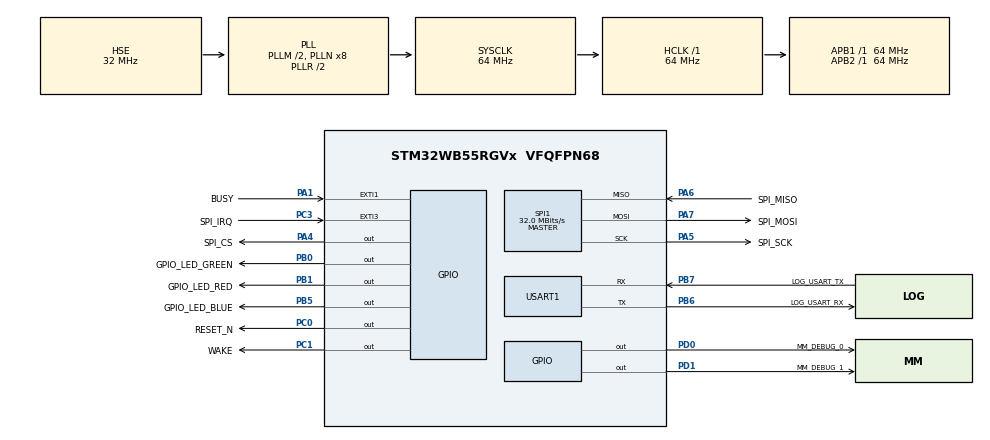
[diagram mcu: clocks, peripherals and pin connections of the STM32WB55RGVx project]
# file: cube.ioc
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Dma.Request0=SPI1_RX
Dma.Request1=SPI1_TX
Dma.SPI1_RX.0.Direction=DMA_PERIPH_TO_MEMORY
Dma.SPI1_RX.0.EventEnable=DISABLE
Dma.SPI1_RX.0.Instance=DMA1_Channel1
Dma.SPI1_RX.0.MemDataAlignment=DMA_MDATAALIGN_BYTE
Dma.SPI1_RX.0.MemInc=DMA_MINC_ENABLE
Dma.SPI1_RX.0.Mode=DMA_NORMAL
Dma.SPI1_RX.0.PeriphDataAlignment=DMA_PDATAALIGN_BYTE
Dma.SPI1_RX.0.PeriphInc=DMA_PINC_DISABLE
Dma.SPI1_RX.0.Polarity=HAL_DMAMUX_REQ_GEN_RISING
Dma.SPI1_RX.0.Priority=DMA_PRIORITY_LOW
Dma.SPI1_RX.0.RequestNumber=1
Dma.SPI1_RX.0.SignalID=NONE
Dma.SPI1_RX.0.SyncEnable=DISABLE
Dma.SPI1_RX.0.SyncPolarity=HAL_DMAMUX_SYNC_NO_EVENT
Dma.SPI1_RX.0.SyncRequestNumber=1
Dma.SPI1_RX.0.SyncSignalID=NONE
Dma.SPI1_TX.1.Direction=DMA_MEMORY_TO_PERIPH
Dma.SPI1_TX.1.EventEnable=DISABLE
Dma.SPI1_TX.1.Instance=DMA1_Channel2
Dma.SPI1_TX.1.MemDataAlignment=DMA_MDATAALIGN_BYTE
Dma.SPI1_TX.1.MemInc=DMA_MINC_ENABLE
Dma.SPI1_TX.1.Mode=DMA_NORMAL
Dma.SPI1_TX.1.PeriphDataAlignment=DMA_PDATAALIGN_BYTE
Dma.SPI1_TX.1.PeriphInc=DMA_PINC_DISABLE
Dma.SPI1_TX.1.Polarity=HAL_DMAMUX_REQ_GEN_RISING
Dma.SPI1_TX.1.Priority=DMA_PRIORITY_LOW
Dma.SPI1_TX.1.RequestNumber=1
Dma.SPI1_TX.1.SignalID=NONE
Dma.SPI1_TX.1.SyncEnable=DISABLE
Dma.SPI1_TX.1.SyncPolarity=HAL_DMAMUX_SYNC_NO_EVENT
Dma.SPI1_TX.1.SyncRequestNumber=1
Dma.SPI1_TX.1.SyncSignalID=NONE
Mcu.Family=STM32WB
Mcu.Name=STM32WB55RGVx
Mcu.Package=VFQFPN68
NVIC.DMA1_Channel1_IRQn=true\:15\:0\:true\:false\:false\:false\:true\:true
NVIC.EXTI1_IRQn=true\:15\:0\:true\:false\:false\:true\:true\:false
NVIC.EXTI3_IRQn=true\:15\:0\:true\:false\:false\:true\:true\:false
NVIC.HSEM_IRQn=true\:5\:0\:true\:false\:true\:false\:true\:true
NVIC.IPCC_C1_RX_IRQn=true\:5\:0\:true\:false\:true\:true\:true\:true
NVIC.IPCC_C1_TX_IRQn=true\:5\:0\:true\:false\:true\:true\:true\:true
NVIC.PriorityGroup=NVIC_PRIORITYGROUP_4
NVIC.TIM1_UP_TIM16_IRQn=true\:15\:0\:false\:false\:true\:false\:true\:true
NVIC.TimeBase=TIM1_UP_TIM16_IRQn
NVIC.TimeBaseIP=TIM1
NVIC.USART1_IRQn=true\:15\:0\:true\:false\:false\:true\:true\:true
OSC_IN.Mode=HSE-External-Oscillator
OSC_IN.Signal=RCC_OSC_IN
OSC_OUT.Mode=HSE-External-Oscillator
OSC_OUT.Signal=RCC_OSC_OUT
PA1.GPIO_Label=BUSY
PA1.GPIO_PuPd=GPIO_PULLDOWN
PA1.Signal=GPXTI1
PA13.GPIO_Label=JTMS
PA13.Mode=Serial_Wire
PA13.Signal=SYS_JTMS-SWDIO
PA14.GPIO_Label=JTCK
PA14.Mode=Serial_Wire
PA14.Signal=SYS_JTCK-SWCLK
PA4.GPIO_Label=SPI_CS
PA4.Signal=GPIO_Output
PA5.GPIO_Label=SPI_SCK
PA5.GPIO_Speed=GPIO_SPEED_FREQ_VERY_HIGH
PA5.Mode=Full_Duplex_Master
PA5.Signal=SPI1_SCK
PA6.GPIO_Label=SPI_MISO
PA6.GPIO_Speed=GPIO_SPEED_FREQ_VERY_HIGH
PA6.Mode=Full_Duplex_Master
PA6.Signal=SPI1_MISO
PA7.GPIO_Label=SPI_MOSI
PA7.GPIO_Speed=GPIO_SPEED_FREQ_VERY_HIGH
PA7.Mode=Full_Duplex_Master
PA7.Signal=SPI1_MOSI
PB0.GPIO_Label=GPIO_LED_GREEN
PB0.Signal=GPIO_Output
PB1.GPIO_Label=GPIO_LED_RED
PB1.Signal=GPIO_Output
PB3.GPIO_Label=JTDO
PB3.Signal=SYS_JTDO-SWO
PB5.GPIO_Label=GPIO_LED_BLUE
PB5.Signal=GPIO_Output
PB6.GPIO_Label=LOG_USART_RX
PB6.GPIO_PuPd=GPIO_NOPULL
PB6.Mode=Asynchronous
PB6.Signal=USART1_TX
PB7.GPIO_Label=LOG_USART_TX
PB7.GPIO_PuPd=GPIO_NOPULL
PB7.Mode=Asynchronous
PB7.Signal=USART1_RX
PC0.GPIO_Label=RESET_N
PC0.Signal=GPIO_Output
PC1.GPIO_Label=WAKE
PC1.Signal=GPIO_Output
PC14-OSC32_IN.Mode=LSE-External-Oscillator
PC14-OSC32_IN.Signal=RCC_OSC32_IN
PC15-OSC32_OUT.Mode=LSE-External-Oscillator
PC15-OSC32_OUT.Signal=RCC_OSC32_OUT
PC3.GPIO_Label=SPI_IRQ
PC3.GPIO_ModeDefaultEXTI=GPIO_MODE_IT_FALLING
PC3.Signal=GPXTI3
PD0.GPIO_Label=MM_DEBUG_0
PD0.Signal=GPIO_Output
PD1.GPIO_Label=MM_DEBUG_1
PD1.Signal=GPIO_Output
ProjectManager.HeapSize=0x200
ProjectManager.StackSize=0x400
ProjectManager.TargetToolchain=STM32CubeIDE
RCC.ADCFreq_Value=192000000
RCC.AHB2CLKDivider=RCC_SYSCLK_DIV2
RCC.AHBFreq_Value=64000000
RCC.APB1Freq_Value=64000000
RCC.APB1TimFreq_Value=64000000
RCC.APB2Freq_Value=64000000
RCC.APB2TimFreq_Value=64000000
RCC.APB3Freq_Value=16000000
RCC.CK48CLockSelection=RCC_USBCLKSOURCE_HSI48
RCC.CortexFreq_Value=64000000
RCC.HCLKFreq_Value=64000000
RCC.HSE_VALUE=32000000
RCC.HSI48_VALUE=48000000
RCC.HSI_VALUE=16000000
RCC.PLLM=RCC_PLLM_DIV2
RCC.PLLSAI1N=24
RCC.PLLSourceVirtual=RCC_PLLSOURCE_HSE
RCC.RFWKPClockSelection=RCC_RFWKPCLKSOURCE_LSE
RCC.RNGCLockSelection=RCC_RNGCLKSOURCE_CLK48
RCC.RTCClockSelection=RCC_RTCCLKSOURCE_LSE
RCC.SMPSCLockSelectionVirtual=RCC_SMPSCLKSOURCE_HSE
RCC.SMPSCLockSelectionVirtualVirtual=RCC_SMPSCLKSOURCE_HSI
RCC.SMPSDivider=4
RCC.SYSCLKFreq_VALUE=64000000
RCC.SYSCLKSource=RCC_SYSCLKSOURCE_PLLCLK
RCC.USBFreq_Value=48000000
RCC.VCOOutputFreq_Value=128000000
RF1.Mode=RF1_Activate
RF1.Signal=RF_RF1
SPI1.BaudRatePrescaler=SPI_BAUDRATEPRESCALER_2
SPI1.CRCCalculation=SPI_CRCCALCULATION_DISABLE
SPI1.CalculateBaudRate=32.0 MBits/s
SPI1.DataSize=SPI_DATASIZE_8BIT
SPI1.Direction=SPI_DIRECTION_2LINES
SPI1.Mode=SPI_MODE_MASTER
SPI1.NSSPMode=SPI_NSS_PULSE_DISABLE
SPI1.VirtualType=VM_MASTER
STM32_WPAN.BLE_APPLICATION_TYPE=BLE_SERVER_PROFILE
STM32_WPAN.BLE_STACK=LIGHT
STM32_WPAN.BT_SIG_HEART_RATE_SENSOR=Enabled
STM32_WPAN.CUSTOM_P2P_SERVER=Disabled
STM32_WPAN.LOCAL_NAME=MM_He
STM32_WPAN.LOCAL_NAME_FORMATTED=,'M','M','_','H','e'
USART1.VirtualMode-Asynchronous=VM_ASYNC
USART1.WordLength=WORDLENGTH_8B
VP_HSEM_VS_HSEM.Mode=HSEM_Activate
VP_IPCC_VS_IPCC.Mode=IPCC_Activate
VP_RNG_VS_RNG.Mode=RNG_Activate
VP_RTC_VS_RTC_Activate.Mode=RTC_Enabled
VP_SEQUENCER_VS_SEQUENCER.Mode=SEQUENCER_Enabled
VP_STM32_WPAN_VS_BLE_HOST.Mode=STM32_WPAN_Enabled
VP_SYS_VS_tim1.Mode=TIM1
VP_TINY_LPM_VS_TINY_LPM.Mode=TINY_LPM_Enabled
board=P-NUCLEO-WB55-Nucleo

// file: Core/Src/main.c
/* USER CODE BEGIN Header */
/**
  ******************************************************************************
  * @file           : main.c
  * @brief          : Main program body
  ******************************************************************************
  * @attention
  *
  * <h2><center>&copy; Copyright (c) 2022 STMicroelectronics.
  * All rights reserved.</center></h2>
  *
  * This software component is licensed by ST under Ultimate Liberty license
  * SLA0044, the "License"; You may not use this file except in compliance with
  * the License. You may obtain a copy of the License at:
  *                             www.st.com/SLA0044
  *
  ******************************************************************************
  */
/* USER CODE END Header */
#include "main.h"

/* USER CODE BEGIN Includes */
#include "mmosal.h"
/* USER CODE END Includes */

IPCC_HandleTypeDef hipcc;

RTC_HandleTypeDef hrtc;

void SystemClock_Config(void);
void PeriphCommonClock_Config(void);
static void MX_GPIO_Init(void);
static void MX_DMA_Init(void);
static void MX_USART1_UART_Init(void);
static void MX_SPI1_Init(void);
static void MX_RNG_Init(void);
static void MX_RTC_Init(void);
static void MX_RF_Init(void);
static void MX_IPCC_Init(void);
/* USER CODE BEGIN PFP */
void app_init(void);
/* USER CODE END PFP */

int main(void)
{

  /* MCU Configuration--------------------------------------------------------*/

  /* Reset of all peripherals, Initializes the Flash interface and the Systick. */
  HAL_Init();
  /* Config code for STM32_WPAN (HSE Tuning must be done before system clock configuration) */
  MX_APPE_Config();

  /* Configure the system clock */
  SystemClock_Config();

/* Configure the peripherals common clocks */
  PeriphCommonClock_Config();

  /* IPCC initialisation */
   MX_IPCC_Init();

  /* Initialize all configured peripherals */
  MX_GPIO_Init();
  MX_DMA_Init();
  MX_USART1_UART_Init();
  MX_SPI1_Init();
  MX_RNG_Init();
  MX_RTC_Init();
  MX_RF_Init();

  /* Init code for STM32_WPAN */
  MX_APPE_Init();

  /* USER CODE BEGIN 2 */
  mmosal_main(app_init);
  /* USER CODE END 2 */

  /* Infinite loop */
  while (1)
  {

  }
}

void SystemClock_Config(void)
{
  RCC_OscInitTypeDef RCC_OscInitStruct = {0};
  RCC_ClkInitTypeDef RCC_ClkInitStruct = {0};

  /** Configure LSE Drive Capability
  */
  HAL_PWR_EnableBkUpAccess();
  __HAL_RCC_LSEDRIVE_CONFIG(RCC_LSEDRIVE_LOW);

  /** Configure the main internal regulator output voltage
  */
  __HAL_PWR_VOLTAGESCALING_CONFIG(PWR_REGULATOR_VOLTAGE_SCALE1);

  /** Initializes the RCC Oscillators according to the specified parameters
  * in the RCC_OscInitTypeDef structure.
  */
  RCC_OscInitStruct.OscillatorType = RCC_OSCILLATORTYPE_HSI48|RCC_OSCILLATORTYPE_HSI
                              |RCC_OSCILLATORTYPE_HSE|RCC_OSCILLATORTYPE_LSE;
  RCC_OscInitStruct.HSEState = RCC_HSE_ON;
  RCC_OscInitStruct.LSEState = RCC_LSE_ON;
  RCC_OscInitStruct.HSIState = RCC_HSI_ON;
  RCC_OscInitStruct.HSI48State = RCC_HSI48_ON;
  RCC_OscInitStruct.HSICalibrationValue = RCC_HSICALIBRATION_DEFAULT;
  RCC_OscInitStruct.PLL.PLLState = RCC_PLL_ON;
  RCC_OscInitStruct.PLL.PLLSource = RCC_PLLSOURCE_HSE;
  RCC_OscInitStruct.PLL.PLLM = RCC_PLLM_DIV2;
  RCC_OscInitStruct.PLL.PLLN = 8;
  RCC_OscInitStruct.PLL.PLLP = RCC_PLLP_DIV2;
  RCC_OscInitStruct.PLL.PLLR = RCC_PLLR_DIV2;
  RCC_OscInitStruct.PLL.PLLQ = RCC_PLLQ_DIV2;
  if (HAL_RCC_OscConfig(&RCC_OscInitStruct) != HAL_OK)
  {
    Error_Handler();
  }

  /** Configure the SYSCLKSource, HCLK, PCLK1 and PCLK2 clocks dividers
  */
  RCC_ClkInitStruct.ClockType = RCC_CLOCKTYPE_HCLK4|RCC_CLOCKTYPE_HCLK2
                              |RCC_CLOCKTYPE_HCLK|RCC_CLOCKTYPE_SYSCLK
                              |RCC_CLOCKTYPE_PCLK1|RCC_CLOCKTYPE_PCLK2;
  RCC_ClkInitStruct.SYSCLKSource = RCC_SYSCLKSOURCE_PLLCLK;
  RCC_ClkInitStruct.AHBCLKDivider = RCC_SYSCLK_DIV1;
  RCC_ClkInitStruct.APB1CLKDivider = RCC_HCLK_DIV1;
  RCC_ClkInitStruct.APB2CLKDivider = RCC_HCLK_DIV1;
  RCC_ClkInitStruct.AHBCLK2Divider = RCC_SYSCLK_DIV2;
  RCC_ClkInitStruct.AHBCLK4Divider = RCC_SYSCLK_DIV1;

  if (HAL_RCC_ClockConfig(&RCC_ClkInitStruct, FLASH_LATENCY_3) != HAL_OK)
  {
    Error_Handler();
  }
}

void PeriphCommonClock_Config(void)
{
  RCC_PeriphCLKInitTypeDef PeriphClkInitStruct = {0};

  /** Initializes the peripherals clock
  */
  PeriphClkInitStruct.PeriphClockSelection = RCC_PERIPHCLK_SMPS|RCC_PERIPHCLK_RFWAKEUP;
  PeriphClkInitStruct.RFWakeUpClockSelection = RCC_RFWKPCLKSOURCE_HSE_DIV1024;
  PeriphClkInitStruct.SmpsClockSelection = RCC_SMPSCLKSOURCE_HSE;
  PeriphClkInitStruct.SmpsDivSelection = RCC_SMPSCLKDIV_RANGE1;

  if (HAL_RCCEx_PeriphCLKConfig(&PeriphClkInitStruct) != HAL_OK)
  {
    Error_Handler();
  }
}

static void MX_IPCC_Init(void)
{

  hipcc.Instance = IPCC;
  if (HAL_IPCC_Init(&hipcc) != HAL_OK)
  {
    Error_Handler();
  }

}

static void MX_RF_Init(void)
{

}

static void MX_RNG_Init(void)
{

  RCC_PeriphCLKInitTypeDef PeriphClkInitStruct = {0};

  /** Initializes the peripherals clock
  */
  PeriphClkInitStruct.PeriphClockSelection = RCC_PERIPHCLK_RNG;
  PeriphClkInitStruct.RngClockSelection = RCC_RNGCLKSOURCE_HSI48;
  if (HAL_RCCEx_PeriphCLKConfig(&PeriphClkInitStruct) != HAL_OK)
  {
    Error_Handler();
  }

  /* Peripheral clock enable */
  LL_AHB3_GRP1_EnableClock(LL_AHB3_GRP1_PERIPH_RNG);

  LL_RNG_Enable(RNG);
  LL_RNG_EnableClkErrorDetect(RNG);

}

static void MX_RTC_Init(void)
{

  /** Initialize RTC Only
  */
  hrtc.Instance = RTC;
  hrtc.Init.HourFormat = RTC_HOURFORMAT_24;
  hrtc.Init.AsynchPrediv = CFG_RTC_ASYNCH_PRESCALER;
  hrtc.Init.SynchPrediv = CFG_RTC_SYNCH_PRESCALER;
  hrtc.Init.OutPut = RTC_OUTPUT_DISABLE;
  hrtc.Init.OutPutPolarity = RTC_OUTPUT_POLARITY_HIGH;
  hrtc.Init.OutPutType = RTC_OUTPUT_TYPE_OPENDRAIN;
  hrtc.Init.OutPutRemap = RTC_OUTPUT_REMAP_NONE;
  if (HAL_RTC_Init(&hrtc) != HAL_OK)
  {
    Error_Handler();
  }
  /* USER CODE BEGIN RTC_Init 2 */
  /** Enable the WakeUp
     */
  if (HAL_RTCEx_SetWakeUpTimer_IT(&hrtc, 0, RTC_WAKEUPCLOCK_RTCCLK_DIV16) != HAL_OK)
  {
      Error_Handler();
  }
  /* USER CODE END RTC_Init 2 */

}

static void MX_SPI1_Init(void)
{

  LL_SPI_InitTypeDef SPI_InitStruct = {0};

  LL_GPIO_InitTypeDef GPIO_InitStruct = {0};

  /* Peripheral clock enable */
  LL_APB2_GRP1_EnableClock(LL_APB2_GRP1_PERIPH_SPI1);

  LL_AHB2_GRP1_EnableClock(LL_AHB2_GRP1_PERIPH_GPIOA);
  /**SPI1 GPIO Configuration
  PA5   ------> SPI1_SCK
  PA6   ------> SPI1_MISO
  PA7   ------> SPI1_MOSI
  */
  GPIO_InitStruct.Pin = SPI_SCK_Pin|SPI_MISO_Pin|SPI_MOSI_Pin;
  GPIO_InitStruct.Mode = LL_GPIO_MODE_ALTERNATE;
  GPIO_InitStruct.Speed = LL_GPIO_SPEED_FREQ_VERY_HIGH;
  GPIO_InitStruct.OutputType = LL_GPIO_OUTPUT_PUSHPULL;
  GPIO_InitStruct.Pull = LL_GPIO_PULL_NO;
  GPIO_InitStruct.Alternate = LL_GPIO_AF_5;
  LL_GPIO_Init(GPIOA, &GPIO_InitStruct);

  /* SPI1 DMA Init */

  /* SPI1_RX Init */
  LL_DMA_SetPeriphRequest(DMA1, LL_DMA_CHANNEL_1, LL_DMAMUX_REQ_SPI1_RX);

  LL_DMA_SetDataTransferDirection(DMA1, LL_DMA_CHANNEL_1, LL_DMA_DIRECTION_PERIPH_TO_MEMORY);

  LL_DMA_SetChannelPriorityLevel(DMA1, LL_DMA_CHANNEL_1, LL_DMA_PRIORITY_LOW);

  LL_DMA_SetMode(DMA1, LL_DMA_CHANNEL_1, LL_DMA_MODE_NORMAL);

  LL_DMA_SetPeriphIncMode(DMA1, LL_DMA_CHANNEL_1, LL_DMA_PERIPH_NOINCREMENT);

  LL_DMA_SetMemoryIncMode(DMA1, LL_DMA_CHANNEL_1, LL_DMA_MEMORY_INCREMENT);

  LL_DMA_SetPeriphSize(DMA1, LL_DMA_CHANNEL_1, LL_DMA_PDATAALIGN_BYTE);

  LL_DMA_SetMemorySize(DMA1, LL_DMA_CHANNEL_1, LL_DMA_MDATAALIGN_BYTE);

  /* SPI1_TX Init */
  LL_DMA_SetPeriphRequest(DMA1, LL_DMA_CHANNEL_2, LL_DMAMUX_REQ_SPI1_TX);

  LL_DMA_SetDataTransferDirection(DMA1, LL_DMA_CHANNEL_2, LL_DMA_DIRECTION_MEMORY_TO_PERIPH);

  LL_DMA_SetChannelPriorityLevel(DMA1, LL_DMA_CHANNEL_2, LL_DMA_PRIORITY_LOW);

  LL_DMA_SetMode(DMA1, LL_DMA_CHANNEL_2, LL_DMA_MODE_NORMAL);

  LL_DMA_SetPeriphIncMode(DMA1, LL_DMA_CHANNEL_2, LL_DMA_PERIPH_NOINCREMENT);

  LL_DMA_SetMemoryIncMode(DMA1, LL_DMA_CHANNEL_2, LL_DMA_MEMORY_INCREMENT);

  LL_DMA_SetPeriphSize(DMA1, LL_DMA_CHANNEL_2, LL_DMA_PDATAALIGN_BYTE);

  LL_DMA_SetMemorySize(DMA1, LL_DMA_CHANNEL_2, LL_DMA_MDATAALIGN_BYTE);

  /* USER CODE BEGIN SPI1_Init 1 */
  LL_DMA_EnableIT_TC(SPI_DMA_PERIPH, SPI_RX_DMA_CHANNEL);
  /* USER CODE END SPI1_Init 1 */
  /* SPI1 parameter configuration*/
  SPI_InitStruct.TransferDirection = LL_SPI_FULL_DUPLEX;
  SPI_InitStruct.Mode = LL_SPI_MODE_MASTER;
  SPI_InitStruct.DataWidth = LL_SPI_DATAWIDTH_8BIT;
  SPI_InitStruct.ClockPolarity = LL_SPI_POLARITY_LOW;
  SPI_InitStruct.ClockPhase = LL_SPI_PHASE_1EDGE;
  SPI_InitStruct.NSS = LL_SPI_NSS_SOFT;
  SPI_InitStruct.BaudRate = LL_SPI_BAUDRATEPRESCALER_DIV2;
  SPI_InitStruct.BitOrder = LL_SPI_MSB_FIRST;
  SPI_InitStruct.CRCCalculation = LL_SPI_CRCCALCULATION_DISABLE;
  SPI_InitStruct.CRCPoly = 7;
  LL_SPI_Init(SPI1, &SPI_InitStruct);
  LL_SPI_SetStandard(SPI1, LL_SPI_PROTOCOL_MOTOROLA);
  LL_SPI_DisableNSSPulseMgt(SPI1);

}

static void MX_USART1_UART_Init(void)
{

  LL_USART_InitTypeDef USART_InitStruct = {0};

  LL_GPIO_InitTypeDef GPIO_InitStruct = {0};
  RCC_PeriphCLKInitTypeDef PeriphClkInitStruct = {0};

  /** Initializes the peripherals clock
  */
  PeriphClkInitStruct.PeriphClockSelection = RCC_PERIPHCLK_USART1;
  PeriphClkInitStruct.Usart1ClockSelection = RCC_USART1CLKSOURCE_PCLK2;
  if (HAL_RCCEx_PeriphCLKConfig(&PeriphClkInitStruct) != HAL_OK)
  {
    Error_Handler();
  }

  /* Peripheral clock enable */
  LL_APB2_GRP1_EnableClock(LL_APB2_GRP1_PERIPH_USART1);

  LL_AHB2_GRP1_EnableClock(LL_AHB2_GRP1_PERIPH_GPIOB);
  /**USART1 GPIO Configuration
  PB6   ------> USART1_TX
  PB7   ------> USART1_RX
  */
  GPIO_InitStruct.Pin = LOG_USART_RX_Pin|LOG_USART_TX_Pin;
  GPIO_InitStruct.Mode = LL_GPIO_MODE_ALTERNATE;
  GPIO_InitStruct.Speed = LL_GPIO_SPEED_FREQ_LOW;
  GPIO_InitStruct.OutputType = LL_GPIO_OUTPUT_PUSHPULL;
  GPIO_InitStruct.Pull = LL_GPIO_PULL_NO;
  GPIO_InitStruct.Alternate = LL_GPIO_AF_7;
  LL_GPIO_Init(GPIOB, &GPIO_InitStruct);

  /* USART1 interrupt Init */
  NVIC_SetPriority(USART1_IRQn, NVIC_EncodePriority(NVIC_GetPriorityGrouping(),15, 0));
  NVIC_EnableIRQ(USART1_IRQn);

  USART_InitStruct.PrescalerValue = LL_USART_PRESCALER_DIV1;
  USART_InitStruct.BaudRate = 115200;
  USART_InitStruct.DataWidth = LL_USART_DATAWIDTH_8B;
  USART_InitStruct.StopBits = LL_USART_STOPBITS_1;
  USART_InitStruct.Parity = LL_USART_PARITY_NONE;
  USART_InitStruct.TransferDirection = LL_USART_DIRECTION_TX_RX;
  USART_InitStruct.HardwareFlowControl = LL_USART_HWCONTROL_NONE;
  USART_InitStruct.OverSampling = LL_USART_OVERSAMPLING_16;
  LL_USART_Init(USART1, &USART_InitStruct);
  LL_USART_SetTXFIFOThreshold(USART1, LL_USART_FIFOTHRESHOLD_1_8);
  LL_USART_SetRXFIFOThreshold(USART1, LL_USART_FIFOTHRESHOLD_1_8);
  LL_USART_DisableFIFO(USART1);
  LL_USART_ConfigAsyncMode(USART1);

  LL_USART_Enable(USART1);

  /* Polling USART1 initialisation */
  while((!(LL_USART_IsActiveFlag_TEACK(USART1))) || (!(LL_USART_IsActiveFlag_REACK(USART1))))
  {
  }

}

static void MX_DMA_Init(void)
{

  /* Init with LL driver */
  /* DMA controller clock enable */
  LL_AHB1_GRP1_EnableClock(LL_AHB1_GRP1_PERIPH_DMAMUX1);
  LL_AHB1_GRP1_EnableClock(LL_AHB1_GRP1_PERIPH_DMA1);

  /* DMA interrupt init */
  /* DMA1_Channel1_IRQn interrupt configuration */
  NVIC_SetPriority(DMA1_Channel1_IRQn, NVIC_EncodePriority(NVIC_GetPriorityGrouping(),15, 0));
  NVIC_EnableIRQ(DMA1_Channel1_IRQn);

}

static void MX_GPIO_Init(void)
{
  LL_EXTI_InitTypeDef EXTI_InitStruct = {0};
  LL_GPIO_InitTypeDef GPIO_InitStruct = {0};

  /* GPIO Ports Clock Enable */
  LL_AHB2_GRP1_EnableClock(LL_AHB2_GRP1_PERIPH_GPIOC);
  LL_AHB2_GRP1_EnableClock(LL_AHB2_GRP1_PERIPH_GPIOA);
  LL_AHB2_GRP1_EnableClock(LL_AHB2_GRP1_PERIPH_GPIOB);

  /**/
  LL_GPIO_ResetOutputPin(GPIOC, RESET_N_Pin|WAKE_Pin);

  /**/
  LL_GPIO_ResetOutputPin(SPI_CS_GPIO_Port, SPI_CS_Pin);

  /**/
  LL_GPIO_ResetOutputPin(GPIOB, GPIO_LED_GREEN_Pin|GPIO_LED_RED_Pin|GPIO_LED_BLUE_Pin);

  /**/
  LL_GPIO_ResetOutputPin(GPIOD, MM_DEBUG_0_Pin|MM_DEBUG_1_Pin);

  /**/
  GPIO_InitStruct.Pin = RESET_N_Pin|WAKE_Pin;
  GPIO_InitStruct.Mode = LL_GPIO_MODE_OUTPUT;
  GPIO_InitStruct.Speed = LL_GPIO_SPEED_FREQ_LOW;
  GPIO_InitStruct.OutputType = LL_GPIO_OUTPUT_PUSHPULL;
  GPIO_InitStruct.Pull = LL_GPIO_PULL_NO;
  LL_GPIO_Init(GPIOC, &GPIO_InitStruct);

  /**/
  GPIO_InitStruct.Pin = SPI_CS_Pin;
  GPIO_InitStruct.Mode = LL_GPIO_MODE_OUTPUT;
  GPIO_InitStruct.Speed = LL_GPIO_SPEED_FREQ_LOW;
  GPIO_InitStruct.OutputType = LL_GPIO_OUTPUT_PUSHPULL;
  GPIO_InitStruct.Pull = LL_GPIO_PULL_NO;
  LL_GPIO_Init(SPI_CS_GPIO_Port, &GPIO_InitStruct);

  /**/
  GPIO_InitStruct.Pin = GPIO_LED_GREEN_Pin|GPIO_LED_RED_Pin|GPIO_LED_BLUE_Pin;
  GPIO_InitStruct.Mode = LL_GPIO_MODE_OUTPUT;
  GPIO_InitStruct.Speed = LL_GPIO_SPEED_FREQ_LOW;
  GPIO_InitStruct.OutputType = LL_GPIO_OUTPUT_PUSHPULL;
  GPIO_InitStruct.Pull = LL_GPIO_PULL_NO;
  LL_GPIO_Init(GPIOB, &GPIO_InitStruct);

  /**/
  GPIO_InitStruct.Pin = MM_DEBUG_0_Pin|MM_DEBUG_1_Pin;
  GPIO_InitStruct.Mode = LL_GPIO_MODE_OUTPUT;
  GPIO_InitStruct.Speed = LL_GPIO_SPEED_FREQ_LOW;
  GPIO_InitStruct.OutputType = LL_GPIO_OUTPUT_PUSHPULL;
  GPIO_InitStruct.Pull = LL_GPIO_PULL_NO;
  LL_GPIO_Init(GPIOD, &GPIO_InitStruct);

  /**/
  LL_SYSCFG_SetEXTISource(LL_SYSCFG_EXTI_PORTC, LL_SYSCFG_EXTI_LINE3);

  /**/
  LL_SYSCFG_SetEXTISource(LL_SYSCFG_EXTI_PORTA, LL_SYSCFG_EXTI_LINE1);

  /**/
  EXTI_InitStruct.Line_0_31 = LL_EXTI_LINE_3;
  EXTI_InitStruct.Line_32_63 = LL_EXTI_LINE_NONE;
  EXTI_InitStruct.LineCommand = ENABLE;
  EXTI_InitStruct.Mode = LL_EXTI_MODE_IT;
  EXTI_InitStruct.Trigger = LL_EXTI_TRIGGER_FALLING;
  LL_EXTI_Init(&EXTI_InitStruct);

  /**/
  EXTI_InitStruct.Line_0_31 = LL_EXTI_LINE_1;
  EXTI_InitStruct.Line_32_63 = LL_EXTI_LINE_NONE;
  EXTI_InitStruct.LineCommand = ENABLE;
  EXTI_InitStruct.Mode = LL_EXTI_MODE_IT;
  EXTI_InitStruct.Trigger = LL_EXTI_TRIGGER_RISING;
  LL_EXTI_Init(&EXTI_InitStruct);

  /**/
  LL_GPIO_SetPinPull(SPI_IRQ_GPIO_Port, SPI_IRQ_Pin, LL_GPIO_PULL_NO);

  /**/
  LL_GPIO_SetPinPull(BUSY_GPIO_Port, BUSY_Pin, LL_GPIO_PULL_DOWN);

  /**/
  LL_GPIO_SetPinMode(SPI_IRQ_GPIO_Port, SPI_IRQ_Pin, LL_GPIO_MODE_INPUT);

  /**/
  LL_GPIO_SetPinMode(BUSY_GPIO_Port, BUSY_Pin, LL_GPIO_MODE_INPUT);

  /* EXTI interrupt init*/
  NVIC_SetPriority(EXTI1_IRQn, NVIC_EncodePriority(NVIC_GetPriorityGrouping(),15, 0));
  NVIC_SetPriority(EXTI3_IRQn, NVIC_EncodePriority(NVIC_GetPriorityGrouping(),15, 0));

}

void HAL_TIM_PeriodElapsedCallback(TIM_HandleTypeDef *htim)
{
  if (htim->Instance == TIM1) {
    HAL_IncTick();
  }
}

void Error_Handler(void)
{
  /* USER CODE BEGIN Error_Handler_Debug */
  /* User can add his own implementation to report the HAL error return state */
  MMOSAL_ASSERT(false);
  while (1)
  {
    MMPORT_BREAKPOINT();
  }
  /* USER CODE END Error_Handler_Debug */
}
